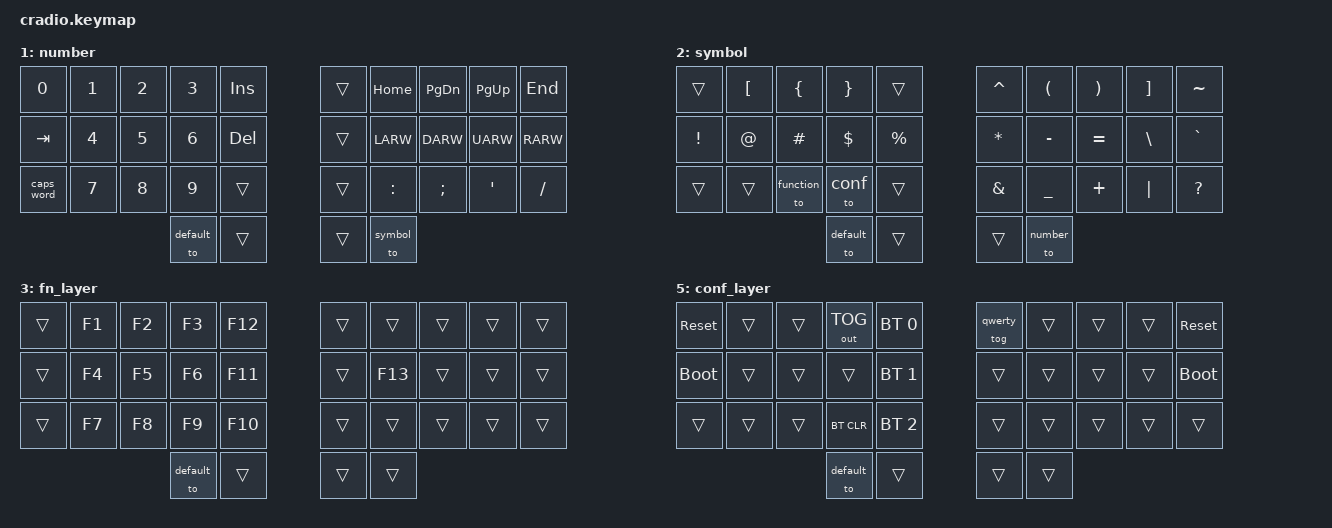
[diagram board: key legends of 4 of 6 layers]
// Copyright (c) 2022 The ZMK Contributors
// SPDX-License-Identifier: MIT

#include <behaviors.dtsi>
#include <dt-bindings/zmk/keys.h>
#include <dt-bindings/zmk/bt.h>
#include <dt-bindings/zmk/outputs.h> 
// see https://zmk.dev/docs/behaviors/outputs for bluetooth/usb toggle

// Home row mods macro
#define HRML(k1,k2,k3,k4) &ht LSHFT k1  &ht LALT k2  &ht LCTRL k3  &ht LGUI k4
#define HRMR(k1,k2,k3,k4) &ht RGUI k1  &ht RCTRL k2  &ht RALT k3  &ht RSHFT k4

// meh key
#define MEH(k1) &ht LS(LA(LC(LGUI))) k1

// layers
#define default 0
#define number 1
#define symbol 2
#define function 3
#define qwerty 4
#define conf 5


&lt {
    flavor = "tap-preferred";
    tapping-term-ms = <220>;
    quick-tap-ms = <200>;
};

/ {
    behaviors {
        ht: hold_tap {
            compatible = "zmk,behavior-hold-tap";
            #binding-cells = <2>;
            flavor = "tap-preferred";
            tapping-term-ms = <220>;
            quick-tap-ms = <200>;
            require-prior-idle-ms = <100>;
            bindings = <&kp>, <&kp>;
        };

    };

    /* conditional_layers { */
    /*     compatible = "zmk,conditional-layers"; */
    /*     tri_layer { */
    /*         if-layers = <number symbol>; */
    /*         then-layer = <conf>; */
    /*     }; */
    /* }; */
    
    keymap {
        compatible = "zmk,keymap";
        default_layer {
            bindings = <
        //╭──────────┬──────────┬──────────┬──────────┬──────────╮       ╭──────────┬──────────┬──────────┬──────────┬──────────╮
        //│  Q       │  W       │  F       │  P       │  B       │       │  J       │  L       │  U       │  Y       │ BACKSPACE│
            &kp Q      &kp W      &kp F      &kp P      &kp B              &kp J      &kp L      &kp U      &kp Y      &kp BSPC
        //├──────────┼──────────┼──────────┼──────────┼──────────┤       ├──────────┼──────────┼──────────┼──────────┼──────────┤
        //│  A       │  R       │  S       │  T       │  G       │       │  M       │  N       │  E       │  I       │ O        │
            HRML(A,        R,        S,         T)     &kp G              &kp M      HRMR(N,        E,         I,        O)
        //├──────────┼──────────┼──────────┼──────────┼──────────┤       ├──────────┼──────────┼──────────┼──────────┼──────────┤
        //│  Z       │  X       │  C       │  D       │  V       │       │  K       │  H       │ , <      │ . >      │ ENTER    │
            &kp Z      &kp X      &kp C      &kp D      &kp V              &kp K      &kp H      &kp COMMA  &kp DOT    &kp ENTER
        //╰──────────┴──────────┴──────────┼──────────┼──────────┤       ├──────────┼──────────┼──────────┴──────────┴──────────╯
                                          // LEADER KEY
                                          &kp F13  &ht  LCTRL ESC   &ht LSHFT SPACE     &to number
        //                                 ╰──────────┴──────────╯       ╰──────────┴──────────╯
            >;    
        };

        number {
            bindings = <
        //╭──────────┬──────────┬──────────┬──────────┬──────────╮   ╭──────────┬──────────┬──────────┬──────────┬──────────╮
        //│ 0        │  1       │  2       │  3       │ INSERT   │   │          │ HOME     │ PAGE DN  │ PAGE UP  │ END      │
            &kp N0     &kp N1     &kp N2     &kp N3     &kp INS        &trans     &kp HOME   &kp PG_DN  &kp PG_UP  &kp END  
        //├──────────┼──────────┼──────────┼──────────┼──────────┤   ├──────────┼──────────┼──────────┼──────────┼──────────┤
        //│ TAB      │  4       │  5       │  6       │ DELETE   │   │          │ LEFT     │ DOWN     │ UP       │ RIGHT    │
            &kp TAB    &kp N4     &kp N5     &kp N6     &kp DEL         &trans     &kp LARW   &kp DARW   &kp UARW   &kp RARW
        //├──────────┼──────────┼──────────┼──────────┼──────────┤   ├──────────┼──────────┼──────────┼──────────┼──────────┤
        //│ CAPS     │  7       │  8       │  9       │          │   │          │  :       │  ;       │  ' "     │  / ?     │
           &caps_word  &kp N7     &kp N8     &kp N9     &trans         &trans     &kp COLON  &kp SEMI   &kp SQT     &kp FSLH
        //╰──────────┴──────────┴──────────┼──────────┼──────────┤   ├──────────┼──────────┼──────────┴──────────┴──────────╯
                                             &to default     &trans        &trans     &to symbol
        //                                 ╰──────────┴──────────╯   ╰──────────┴──────────╯
            >;
        };

        symbol {
            bindings = <
        //╭──────────┬──────────┬──────────┬──────────┬──────────╮   ╭──────────┬──────────┬──────────┬──────────┬──────────╮
        //│          │  [       │  {       │  }       │          │   │  ^       │  (       │  )       │  ]       │  ~       │
            &trans     &kp LBKT   &kp LBRC   &kp RBRC   &trans         &kp CARET  &kp LPAR   &kp RPAR   &kp RBKT   &kp TILDE
        //├──────────┼──────────┼──────────┼──────────┼──────────┤   ├──────────┼──────────┼──────────┼──────────┼──────────┤
        //│  !       │  @       │#         │  $       │  %       │   │  *       │  -       │  =       │  \       │  `       │
            &kp EXCL   &kp AT     &kp HASH   &kp DLLR   &kp PRCNT      &kp ASTRK  &kp MINUS  &kp EQUAL  &kp BSLH   &kp GRAVE
        //├──────────┼──────────┼──────────┼──────────┼──────────┤   ├──────────┼──────────┼──────────┼──────────┼──────────┤
        //│          │          │ FN LAYER │  CONF    │          │   │  &       │  _       │  +       │  │       │  ?       │
            &trans     &trans   &to function &to conf    &trans       &kp AMPS   &kp UNDER  &kp PLUS   &kp PIPE  &kp QMARK
        //╰──────────┴──────────┴──────────┼──────────┼──────────┤   ├──────────┼──────────┼──────────┴──────────┴──────────╯
                                           &to default   &trans         &trans    &to number
        //                                 ╰──────────┴──────────╯   ╰──────────┴──────────╯
            >;
        };

        fn_layer {
            bindings = <
        //╭──────────┬──────────┬──────────┬──────────┬──────────╮   ╭──────────┬──────────┬──────────┬──────────┬──────────╮
        //│          │          │          │          │          │   │          │          │          │          │          │
            &trans     &kp F1    &kp F2     &kp F3      &kp F12         &trans     &trans     &trans     &trans     &trans    
        //├──────────┼──────────┼──────────┼──────────┼──────────┤   ├──────────┼──────────┼──────────┼──────────┼──────────┤
        //│          │          │          │          │          │   │        TODO: remap FN key      │          │          │
            &trans     &kp F4     &kp F5     &kp F6     &kp F11         &trans     &kp F13  &trans     &trans    &trans
        //├──────────┼──────────┼──────────┼──────────┼──────────┤   ├──────────┼──────────┼──────────┼──────────┼──────────┤
        //│          │          │          │          │          │   │          │          │          │          │          │
            &trans     &kp F7     &kp F8    &kp F9      &kp F10         &trans     &trans     &trans     &trans     &trans
        //╰──────────┴──────────┴──────────┼──────────┼──────────┤   ├──────────┼──────────┼──────────┴──────────┴──────────╯
                                             &to default     &trans         &trans     &trans
        //                                 ╰──────────┴──────────╯   ╰──────────┴──────────╯
            >;
        };

        qwerty_layer {
            bindings = <
        //╭──────────┬──────────┬──────────┬──────────┬──────────╮   ╭──────────┬──────────┬──────────┬──────────┬──────────╮
        //│  Q       │  W       │  E       │  R       │  T       │   │  Y       │  U       │  I       │  O       │  P       │
            &kp Q      &kp W      &kp E      &kp R      &kp T          &kp Y      &kp U      &kp I      &kp O      &kp P
        //├──────────┼──────────┼──────────┼──────────┼──────────┤   ├──────────┼──────────┼──────────┼──────────┼──────────┤
        //│  A       │  S       │  D       │  F       │  G       │   │  H       │  J       │  K       │  L       │ ' "      │
            HRML(A,        S,         D,         F)     &kp G          &kp H      HRMR(J,        K,         L,        SQT)
        //├──────────┼──────────┼──────────┼──────────┼──────────┤   ├──────────┼──────────┼──────────┼──────────┼──────────┤
        //│  Z       │  X       │  C       │  V       │  B       │   │  N       │  M       │ , <      │ . >      │ / ?      │
            &kp Z      &kp X      &kp C      &kp V      &kp B          &kp N      &kp M      &kp COMMA  &kp DOT    &kp FSLH
        //╰──────────┴──────────┴──────────┼──────────┼──────────┤   ├──────────┼──────────┼──────────┴──────────┴──────────╯
                                        &lt symbol TAB &ht LSHIFT ENTER   &kp SPACE  &lt number BSPC
        //                                 ╰──────────┴──────────╯   ╰──────────┴──────────╯
            >;
        };

        conf_layer {
            bindings = <
        //╭──────────┬──────────┬──────────┬──────────┬──────────╮   ╭──────────┬──────────┬──────────┬──────────┬──────────╮
        //│ RESET    │          │          │TOG BT/USB│PROFILE 0 │   │ QWERTY   │          │          │          │  RESET   │
           &sys_reset  &trans     &trans  &out OUT_TOG &bt BT_SEL 0   &tog qwerty &trans     &trans     &trans    &sys_reset
        //├──────────┼──────────┼──────────┼──────────┼──────────┤   ├──────────┼──────────┼──────────┼──────────┼──────────┤
        //│BOOTLOADER│          │          │          │PROFILE 1 │   │          │          │          │          │BOOTLOADER│
          &bootloader  &trans     &trans     &trans    &bt BT_SEL 1    &trans     &trans     &trans     &trans    &bootloader
        //├──────────┼──────────┼──────────┼──────────┼──────────┤   ├──────────┼──────────┼──────────┼──────────┼──────────┤
        //│          │          │          │ CLEAR BT │PROFILE 2 │   │          │          │          │          │          │
            &trans     &trans     &trans    &bt BT_CLR &bt BT_SEL 2   &trans  &trans     &trans     &trans     &trans
        //╰──────────┴──────────┴──────────┼──────────┼──────────┤   ├──────────┼──────────┼──────────┴──────────┴──────────╯
                                             &to default     &trans         &trans     &trans
        //                                 ╰──────────┴──────────╯   ╰──────────┴──────────╯
            >;
        };

    };
};
